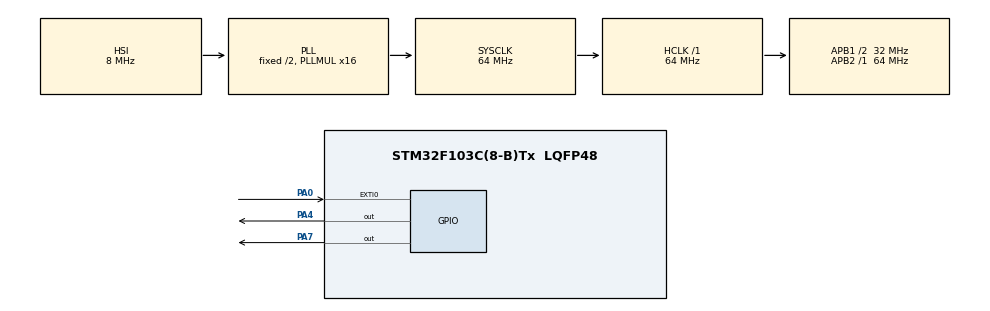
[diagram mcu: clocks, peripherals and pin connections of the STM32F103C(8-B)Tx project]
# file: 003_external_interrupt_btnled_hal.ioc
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Mcu.Family=STM32F1
Mcu.Name=STM32F103C(8-B)Tx
Mcu.Package=LQFP48
NVIC.EXTI0_IRQn=true\:0\:0\:false\:false\:true\:true\:true\:true
NVIC.PriorityGroup=NVIC_PRIORITYGROUP_4
PA0-WKUP.GPIO_PuPd=GPIO_PULLDOWN
PA0-WKUP.Signal=GPXTI0
PA13.Mode=Serial_Wire
PA13.Signal=SYS_JTMS-SWDIO
PA14.Mode=Serial_Wire
PA14.Signal=SYS_JTCK-SWCLK
PA4.Signal=GPIO_Output
PA7.Signal=GPIO_Output
ProjectManager.HeapSize=0x200
ProjectManager.StackSize=0x400
ProjectManager.TargetToolchain=STM32CubeIDE
RCC.AHBFreq_Value=64000000
RCC.APB1CLKDivider=RCC_HCLK_DIV2
RCC.APB1Freq_Value=32000000
RCC.APB1TimFreq_Value=64000000
RCC.APB2Freq_Value=64000000
RCC.APB2TimFreq_Value=64000000
RCC.HCLKFreq_Value=64000000
RCC.PLLMUL=RCC_PLL_MUL16
RCC.SYSCLKFreq_VALUE=64000000
RCC.SYSCLKSource=RCC_SYSCLKSOURCE_PLLCLK
RCC.USBFreq_Value=64000000
board=custom

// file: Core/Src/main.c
/* USER CODE BEGIN Header */
/**
  ******************************************************************************
  * @file           : main.c
  * @brief          : Main program body
  ******************************************************************************
  * @attention
  *
  * Copyright (c) 2024 STMicroelectronics.
  * All rights reserved.
  *
  * This software is licensed under terms that can be found in the LICENSE file
  * in the root directory of this software component.
  * If no LICENSE file comes with this software, it is provided AS-IS.
  *
  ******************************************************************************
  */
/* USER CODE END Header */
#include "main.h"

/* USER CODE BEGIN Includes */
int count = 0;
int i = 0;

/* USER CODE END Includes */

void SystemClock_Config(void);
static void MX_GPIO_Init(void);

/* USER CODE BEGIN 0 */

void HAL_GPIO_EXTI_Callback(uint16_t GPIO_Pin){
	i++;

	if(i == 1){

		count = 1000;
	}
	else if(i == 2){
		count = 500;
	}
	else{
		count = 100;
		i = 0;
	}
}

/* USER CODE END 0 */

int main(void)
{

  /* MCU Configuration--------------------------------------------------------*/

  /* Reset of all peripherals, Initializes the Flash interface and the Systick. */
  HAL_Init();

  /* Configure the system clock */
  SystemClock_Config();

  /* Initialize all configured peripherals */
  MX_GPIO_Init();

  /* Infinite loop */
  while (1)
  {

    /* USER CODE BEGIN 3 */
	  HAL_GPIO_TogglePin(GPIOA, GPIO_PIN_4 | GPIO_PIN_7);
	  HAL_Delay(count);

  }
  /* USER CODE END 3 */
}

void SystemClock_Config(void)
{
  RCC_OscInitTypeDef RCC_OscInitStruct = {0};
  RCC_ClkInitTypeDef RCC_ClkInitStruct = {0};

  /** Initializes the RCC Oscillators according to the specified parameters
  * in the RCC_OscInitTypeDef structure.
  */
  RCC_OscInitStruct.OscillatorType = RCC_OSCILLATORTYPE_HSI;
  RCC_OscInitStruct.HSIState = RCC_HSI_ON;
  RCC_OscInitStruct.HSICalibrationValue = RCC_HSICALIBRATION_DEFAULT;
  RCC_OscInitStruct.PLL.PLLState = RCC_PLL_ON;
  RCC_OscInitStruct.PLL.PLLSource = RCC_PLLSOURCE_HSI_DIV2;
  RCC_OscInitStruct.PLL.PLLMUL = RCC_PLL_MUL16;
  if (HAL_RCC_OscConfig(&RCC_OscInitStruct) != HAL_OK)
  {
    Error_Handler();
  }

  /** Initializes the CPU, AHB and APB buses clocks
  */
  RCC_ClkInitStruct.ClockType = RCC_CLOCKTYPE_HCLK|RCC_CLOCKTYPE_SYSCLK
                              |RCC_CLOCKTYPE_PCLK1|RCC_CLOCKTYPE_PCLK2;
  RCC_ClkInitStruct.SYSCLKSource = RCC_SYSCLKSOURCE_PLLCLK;
  RCC_ClkInitStruct.AHBCLKDivider = RCC_SYSCLK_DIV1;
  RCC_ClkInitStruct.APB1CLKDivider = RCC_HCLK_DIV2;
  RCC_ClkInitStruct.APB2CLKDivider = RCC_HCLK_DIV1;

  if (HAL_RCC_ClockConfig(&RCC_ClkInitStruct, FLASH_LATENCY_2) != HAL_OK)
  {
    Error_Handler();
  }
}

static void MX_GPIO_Init(void)
{
  GPIO_InitTypeDef GPIO_InitStruct = {0};

  /* GPIO Ports Clock Enable */
  __HAL_RCC_GPIOA_CLK_ENABLE();

  /*Configure GPIO pin Output Level */
  HAL_GPIO_WritePin(GPIOA, GPIO_PIN_4|GPIO_PIN_7, GPIO_PIN_RESET);

  /*Configure GPIO pin : PA0 */
  GPIO_InitStruct.Pin = GPIO_PIN_0;
  GPIO_InitStruct.Mode = GPIO_MODE_IT_RISING;
  GPIO_InitStruct.Pull = GPIO_PULLDOWN;
  HAL_GPIO_Init(GPIOA, &GPIO_InitStruct);

  /*Configure GPIO pins : PA4 PA7 */
  GPIO_InitStruct.Pin = GPIO_PIN_4|GPIO_PIN_7;
  GPIO_InitStruct.Mode = GPIO_MODE_OUTPUT_PP;
  GPIO_InitStruct.Pull = GPIO_NOPULL;
  GPIO_InitStruct.Speed = GPIO_SPEED_FREQ_LOW;
  HAL_GPIO_Init(GPIOA, &GPIO_InitStruct);

  /* EXTI interrupt init*/
  HAL_NVIC_SetPriority(EXTI0_IRQn, 0, 0);
  HAL_NVIC_EnableIRQ(EXTI0_IRQn);

}

void Error_Handler(void)
{
  __disable_irq();
  while (1)
  {
  }
}
